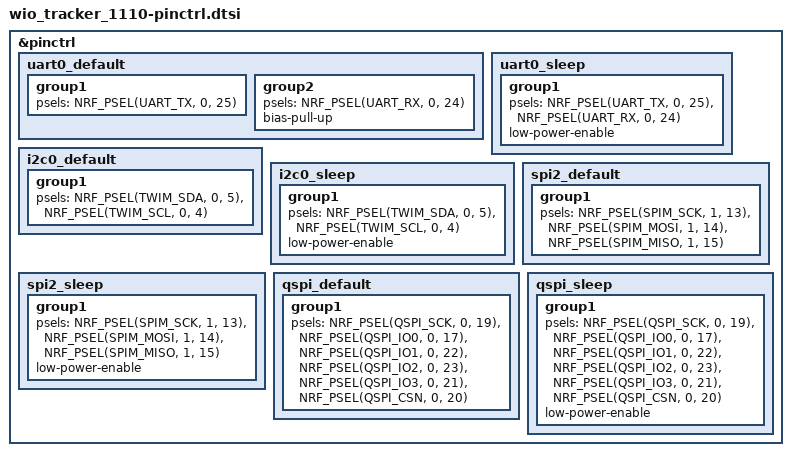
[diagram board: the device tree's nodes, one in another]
&pinctrl {
	uart0_default: uart0_default {
		group1 {
			psels = <NRF_PSEL(UART_TX, 0, 25)>;
		};
		group2 {
			psels = <NRF_PSEL(UART_RX, 0, 24)>;
			bias-pull-up;
		};
	};

	uart0_sleep: uart0_sleep {
		group1 {
			psels = <NRF_PSEL(UART_TX, 0, 25)>,
				<NRF_PSEL(UART_RX, 0, 24)>;
			low-power-enable;
		};
	};

	i2c0_default: i2c0_default {
		group1 {
			psels = <NRF_PSEL(TWIM_SDA, 0, 5)>,
				<NRF_PSEL(TWIM_SCL, 0, 4)>;
		};
	};

	i2c0_sleep: i2c0_sleep {
		group1 {
			psels = <NRF_PSEL(TWIM_SDA, 0, 5)>,
				<NRF_PSEL(TWIM_SCL, 0, 4)>;
			low-power-enable;
		};
	};

	spi2_default: spi2_default {
		group1 {
			psels = <NRF_PSEL(SPIM_SCK, 1, 13)>,
				<NRF_PSEL(SPIM_MOSI, 1, 14)>,
				<NRF_PSEL(SPIM_MISO, 1, 15)>;
		};
	};

	spi2_sleep: spi2_sleep {
		group1 {
			psels = <NRF_PSEL(SPIM_SCK, 1, 13)>,
				<NRF_PSEL(SPIM_MOSI, 1, 14)>,
				<NRF_PSEL(SPIM_MISO, 1, 15)>;
			low-power-enable;
		};
	};

	qspi_default: qspi_default {
		group1 {
			psels = <NRF_PSEL(QSPI_SCK, 0, 19)>,
				<NRF_PSEL(QSPI_IO0, 0, 17)>,
				<NRF_PSEL(QSPI_IO1, 0, 22)>,
				<NRF_PSEL(QSPI_IO2, 0, 23)>,
				<NRF_PSEL(QSPI_IO3, 0, 21)>,
				<NRF_PSEL(QSPI_CSN, 0, 20)>;
		};
	};

	qspi_sleep: qspi_sleep {
		group1 {
			psels = <NRF_PSEL(QSPI_SCK, 0, 19)>,
				<NRF_PSEL(QSPI_IO0, 0, 17)>,
				<NRF_PSEL(QSPI_IO1, 0, 22)>,
				<NRF_PSEL(QSPI_IO2, 0, 23)>,
				<NRF_PSEL(QSPI_IO3, 0, 21)>,
				<NRF_PSEL(QSPI_CSN, 0, 20)>;
			low-power-enable;
		};
	};
};
